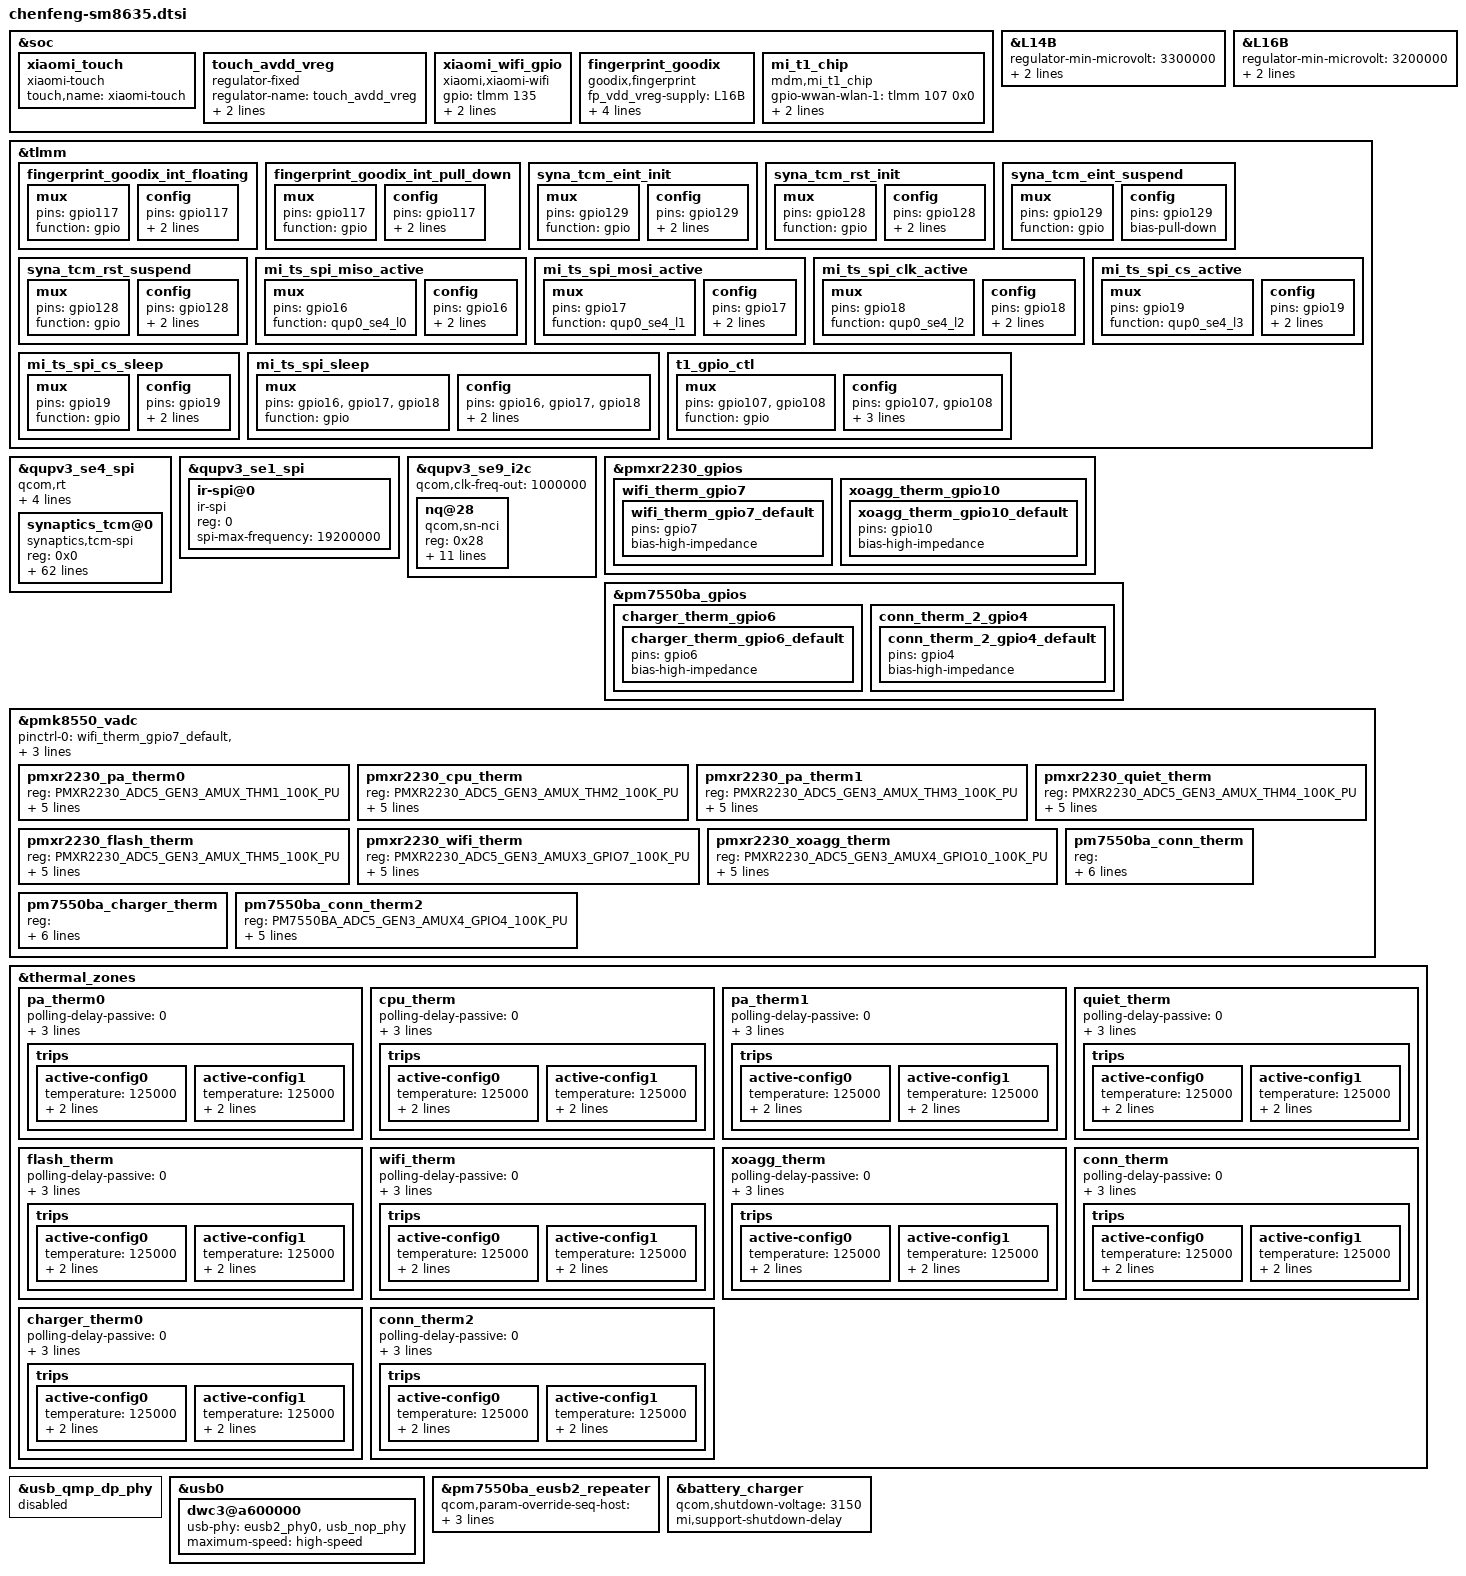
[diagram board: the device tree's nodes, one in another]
/*
  this file is for attribution only of chenfeng
  And public attribution of xiaomi platforms(like N16T and so and)
*/
#define PERIDOT_REGULATOR_OCP_CHENFENG
#include "chenfeng-pinctrl.dtsi"
#include "xiaomi-sm8635-common.dtsi"
#include "cliffs-pm7550ba.dtsi"

&soc {
	xiaomi_touch {
		compatible = "xiaomi-touch";
		status = "ok";
		touch,name = "xiaomi-touch";
	};

	touch_avdd_vreg: touch_avdd_vreg {
		compatible = "regulator-fixed";
		regulator-name = "touch_avdd_vreg";
		/*startup-delay-us = <4000>;*/
		enable-active-high;
		/*regulator-boot-on*/
		gpio = <&tlmm 46 0>;
	};

	xiaomi_wifi_gpio {
		compatible = "xiaomi,xiaomi-wifi";
		gpio = <&tlmm 135 0x00>;
		debounce-time = <30>;
		pinctrl-names = "default";
		pinctrl-0 = <&wifi_ctrl_irq>;
		status = "ok";
	};
};

&L14B {
	regulator-min-microvolt = <3300000>;
	regulator-max-microvolt = <3300000>;
	qcom,init-voltage = <3300000>;
};

&soc {
	fingerprint_goodix {
		compatible = "goodix,fingerprint";
		fp_vdd_vreg-supply = <&L16B>;
		goodix,gpio-reset = <&tlmm 55 0x0>;
		goodix,gpio-irq = <&tlmm 117 0x0>;
		pinctrl-names = "fingerprint_goodix_default", "fingerprint_goodix_rst";
		pinctrl-0 = <&fingerprint_goodix_int_floating>;
		pinctrl-1 = <&fingerprint_goodix_int_pull_down>;
		status = "ok";
	};

	mi_t1_chip {
		compatible = "mdm,mi_t1_chip";
		gpio-wwan-wlan-1 = <&tlmm 107 0x0>;
		gpio-wwan-wlan-2 = <&tlmm 108 0x0>;
		pinctrl-0       = <&t1_gpio_ctl>;
	};
};

&L16B {
	regulator-min-microvolt = <3200000>;
	regulator-max-microvolt = <3200000>;
	qcom,init-voltage = <3200000>;
};

&tlmm {
	fingerprint_goodix_int_floating: fingerprint_goodix_int_floating {
		mux {
			pins = "gpio117";
			function = "gpio";
		};
		config {
			pins = "gpio117";
			input-enable;
			bias-disable;
		};
	};
	fingerprint_goodix_int_pull_down: fingerprint_goodix_int_pull_down {
		mux {
			pins = "gpio117";
			function = "gpio";
		};
		config {
			pins = "gpio117";
			input-enable;
			bias-pull-down;
		};
	};
};

&tlmm {
	syna_tcm_eint_init: syna_tcm_eint_init {
		mux {
			/* GPIO 162 Interrupt */
			pins = "gpio129";
			function = "gpio";
		};

		config {
			pins = "gpio129";
			bias-disable;
			input-enable;
		};
	};

	syna_tcm_rst_init: syna_tcm_rst_init {
		mux {
			/* GPIO 161 Interrupt */
			pins = "gpio128";
			function = "gpio";
		};

		config {
			pins = "gpio128";
			bias-disable;
			output-low;
		};
	};

	syna_tcm_eint_suspend: syna_tcm_eint_suspend {
		mux {
			/* GPIO 162 Interrupt */
			pins = "gpio129";
			function = "gpio";
		};

		config {
			pins = "gpio129";
			bias-pull-down;
		};
	};

	syna_tcm_rst_suspend: syna_tcm_rst_suspend {
		mux {
			/* GPIO 161 Interrupt */
			pins = "gpio128";
			function = "gpio";
		};

		config {
			pins = "gpio128";
			bias-pull-down;
			output-low;
		};
	};
		mi_ts_spi_miso_active: mi_ts_spi_miso_active {
		mux {
			pins = "gpio16";
			function = "qup0_se4_l0";
		};
		config {
			pins = "gpio16";
			drive-strength = <6>;
			bias-pull-down;
		};
	};

	mi_ts_spi_mosi_active: mi_ts_spi_mosi_active {
		mux {
			pins = "gpio17";
			function = "qup0_se4_l1";
		};
		config {
			pins = "gpio17";
			drive-strength = <6>;
			bias-pull-down;
		};
	};

	mi_ts_spi_clk_active: mi_ts_spi_clk_active {
		mux {
			pins = "gpio18";
			function = "qup0_se4_l2";
		};
		config {
			pins = "gpio18";
			drive-strength = <6>;
			bias-pull-down;
		};
	};

	mi_ts_spi_cs_active: mi_ts_spi_cs_active {
		mux {
			pins = "gpio19";
			function = "qup0_se4_l3";
		};
		config {
			pins = "gpio19";
			drive-strength = <6>;
			bias-pull-down;
		};
	};


	mi_ts_spi_cs_sleep: mi_ts_spi_cs_sleep {
		mux {
			pins = "gpio19";
			function = "gpio";
		};
		config {
			pins = "gpio19";
			drive-strength = <6>;
			output-high;
		};
	};


	mi_ts_spi_sleep: mi_ts_spi_sleep {
		mux {
			pins = "gpio16", "gpio17",
				"gpio18";
			function = "gpio";
		};
		config {
			pins = "gpio16", "gpio17",
				"gpio18";
			drive-strength = <2>;
			bias-pull-down;
		};
	};

	t1_gpio_ctl: t1_gpio_ctl {
		mux {
			pins = "gpio107", "gpio108";
			function = "gpio";
		};
		config {
			pins = "gpio107", "gpio108";
			drive-strength = <2>;
			bias-disable;
			output-enable;
		};
	};
};

&qupv3_se4_spi {
	status = "ok";
	qcom,rt;
	pinctrl-0 = <&mi_ts_spi_mosi_active>, <&mi_ts_spi_miso_active>,
		    <&mi_ts_spi_clk_active>, <&mi_ts_spi_cs_active>;
	pinctrl-1 = <&mi_ts_spi_sleep>, <&mi_ts_spi_cs_sleep>;
	synaptics_tcm@0 {
		compatible = "synaptics,tcm-spi";
		reg = <0x0>;
		spi-max-frequency = <10000000>;
		interrupt-parent = <&tlmm>;
		interrupts = <129 0x2008>;
		synaptics,avdd-name = "avdd";
		avdd-supply = <&L14B>;
		synaptics,iovdd-name = "iovdd";
		iovdd-supply = <&touch_avdd_vreg>;
		/*synaptics,bus-reg-name = "vdd";*/
		/*synaptics,pwr-reg-name = "avdd";*/
		synaptics,irq-gpio = <&tlmm 129 0x2008>;
		synaptics,reset-gpio = <&tlmm 128 0x00>;
		synaptics,irq-on-state = <0>;
		synaptics,spi-mode = <0>;
		synaptics,byte-delay-us = <0>;
		synaptics,block-delay-us = <0>;
		synaptics,power-delay-ms = <50>;
		synaptics,reset-active-ms = <10>;
		synaptics,reset-delay-ms = <200>;
		pinctrl-names = "pmx_ts_active","pmx_ts_suspend";
		pinctrl-0 = <&syna_tcm_eint_init &syna_tcm_rst_init>;
		pinctrl-1 = <&syna_tcm_eint_suspend &syna_tcm_rst_suspend>;
		synaptics,default-test-limit-name = "chenfeng_limit_S3905S.csv";
		mi_tp,game-mode-array =
				<1 0 0 0 0>;  /* MAX MIN DEF SET GET	*/
		mi_tp,active-mode-array =
				<1 0 0 0 0>;  /* MAX MIN DEF SET GET	*/
		mi_tp,tolerance-array =
				<4 0 2 2 2>;  /* MAX MIN DEF SET GET	*/
		mi_tp,up-threshold-array =
				<4 0 3 3 3>;  /* MAX MIN DEF SET GET	*/
		mi_tp,aim-sensitivity-array =
				<4 0 2 2 2>;  /* MAX MIN DEF SET GET	*/
		mi_tp,tap-stability-array =
				<4 0 2 2 2>;  /* MAX MIN DEF SET GET	*/
		mi_tp,edge-filter-array =
				<3 0 2 2 2>;  /* MAX MIN DEF SET GET	*/
		mi_tp,panel-orien-array =
				<3 0 0 0 0>;  /* MAX MIN DEF SET GET	*/
		mi_tp,report-rate-array =
				<3 0 0 0 0>;  /* MAX MIN DEF SET GET	*/
		mi_tp,expert-mode-array =
				<3 1 1 1 1>;  /* MAX MIN DEF SET GET	*/
		mi_tp,cornerfilter-area-step-array = <0 100 170 250>; /* step 0 to step 3 */
		mi_tp,cornerzone-filter-hor1-array =
                /* B0:Type, B1:pos, B2:x0, B3:y0, B4:x1, B5:y1, B6:reserved, B7: reserved */
                        <0 0 0 0 170 170 0 0>,
                        <0 1 0 0 0 0 0 0>,
                        <0 2 0 2579 170 2749 0 0>,
                        <0 3 0 0 0 0 0 0>;
		mi_tp,cornerzone-filter-hor2-array =
                /* B0:Type, B1:pos, B2:x0, B3:y0, B4:x1, B5:y1, B6:reserved, B7: reserved */
                        <0 0 0 0 0 0 0 0>,
                        <0 1 1065 0 1235 170 0 0>,
                        <0 2 0 0 0 0 0 0>,
                        <0 3 1065 2579 1235 2749 0 0>;
		mi_tp,cornerzone-filter-ver-array =
                /* B0:Type, B1:pos, B2:x0, B3:y0, B4:x1, B5:y1, B6:reserved, B7: reserved */
                        <0 0 0 0 0 0 0 0>,
                        <0 1 0 0 0 0 0 0>,
                        <0 2 0 2449 150 2749 0 0>,
                        <0 3 1085 2449 1235 2749 0 0>;
		mi_tp,deadzone-filter-hor-array =
                /* B0:Type, B1:pos, B2:x0, B3:y0, B4:x1, B5:y1, B6:reserved, B7: reserved */
                        <2 0 0 0 1235 2 0 0>,
                        <2 1 0 2747 1235 2749 0 0>,
                        <2 2 0 0 2 2749 0 0>,
                        <2 3 1233 0 1235 2479 0 0>;
		mi_tp,deadzone-filter-ver-array =
                /* B0:Type, B1:pos, B2:x0, B3:y0, B4:x1, B5:y1, B6:reserved, B7: reserved */
                        <2 0 0 0 1235 2 0 0>,
                        <2 1 0 2747 1235 2749 0 0>,
                        <2 2 0 0 2 2749 0 0>,
                        <2 3 1233 0 1235 2749 0 0>;
		mi_tp,edgezone-filter-hor-array =
                /* B0:Type, B1:pos, B2:x0, B3:y0, B4:x1, B5:y1, B6:reserved, B7: reserved */
                        <1 0 0 0 1235 40 0 0>,
                        <1 1 0 2709 1235 2749 0 0>,
                        <1 2 0 0 40 2749 0 0>,
                        <1 3 1195 0 1235 2749 0 0>;
		mi_tp,edgezone-filter-ver-array =
                /* B0:Type, B1:pos, B2:x0, B3:y0, B4:x1, B5:y1, B6:reserved, B7: reserved */
                        <1 0 0 0 1235 10 0 0>,
                        <1 1 0 2739 1235 2749 0 0>,
                        <1 2 0 0 40 2749 0 0>,
                        <1 3 1195 0 1235 2749 0 0>;
	};
};

&qupv3_se1_spi {
	status = "ok";
	ir-spi@0 {
		compatible = "ir-spi";
		reg = <0>;
		spi-max-frequency = <19200000>;
		status = "ok";
	};
};

&qupv3_se9_i2c {
	status = "ok";
	qcom,clk-freq-out = <1000000>;
	#address-cells = <1>;
	#size-cells = <0>;
	nq@28 {
		compatible = "qcom,sn-nci";
		reg = <0x28>;
		qcom,sn-irq = <&tlmm 61 0x00>;
		qcom,sn-ven = <&tlmm 114 0x00>;
		qcom,sn-clkreq = <&tlmm 115 0x00>;
		qcom,sn-szone = "enable";
		qcom,sn-vdd-1p8-supply = <&L5B>;
		qcom,sn-vdd-1p8-voltage = <1200000 1200000>;
		qcom,sn-vdd-1p8-current = <157000>;
		interrupt-parent = <&tlmm>;
		interrupts = <61 0>;
		interrupt-names = "nfc_irq";
		pinctrl-names = "nfc_active", "nfc_suspend";
		pinctrl-0 = <&nfc_int_active &nfc_enable_active>;
		pinctrl-1 = <&nfc_int_suspend &nfc_enable_suspend>;
    };
};

&pmxr2230_gpios {
    wifi_therm_gpio7 {
        wifi_therm_gpio7_default: wifi_therm_gpio7_default {
            pins = "gpio7";
            bias-high-impedance;
        };
    };
    xoagg_therm_gpio10 {
        xoagg_therm_gpio10_default: xoagg_therm_gpio10_default {
            pins = "gpio10";
            bias-high-impedance;
        };
    };
};

&pm7550ba_gpios {
    charger_therm_gpio6 {
        charger_therm_gpio6_default: charger_therm_gpio6_default {
            pins = "gpio6";
            bias-high-impedance;
        };
    };
    conn_therm_2_gpio4 {
        conn_therm_2_gpio4_default: conn_therm_2_gpio4_default {
            pins = "gpio4";
            bias-high-impedance;
        };
    };
};
&pmk8550_vadc {
    pinctrl-names = "default";
    pinctrl-0 = <&wifi_therm_gpio7_default &xoagg_therm_gpio10_default &charger_therm_gpio6_default &conn_therm_2_gpio4_default>;

    pmxr2230_pa_therm0 {
        reg = <PMXR2230_ADC5_GEN3_AMUX_THM1_100K_PU>;
        label = "pmxr2230_pa_therm0";
        qcom,ratiometric;
        qcom,hw-settle-time = <200>;
        qcom,pre-scaling = <1 1>;
        qcom,adc-tm-type = <1>;
    };

    pmxr2230_cpu_therm {
        reg = <PMXR2230_ADC5_GEN3_AMUX_THM2_100K_PU>;
        label = "pmxr2230_cpu_therm";
        qcom,ratiometric;
        qcom,hw-settle-time = <200>;
        qcom,pre-scaling = <1 1>;
        qcom,adc-tm-type = <1>;
    };

    pmxr2230_pa_therm1 {
        reg = <PMXR2230_ADC5_GEN3_AMUX_THM3_100K_PU>;
        label = "pmxr2230_pa_therm1";
        qcom,ratiometric;
        qcom,hw-settle-time = <200>;
        qcom,pre-scaling = <1 1>;
        qcom,adc-tm-type = <1>;
    };

    pmxr2230_quiet_therm {
        reg = <PMXR2230_ADC5_GEN3_AMUX_THM4_100K_PU>;
        label = "pmxr2230_quiet_therm";
        qcom,ratiometric;
        qcom,hw-settle-time = <200>;
        qcom,pre-scaling = <1 1>;
        qcom,adc-tm-type = <1>;
    };

    pmxr2230_flash_therm {
        reg = <PMXR2230_ADC5_GEN3_AMUX_THM5_100K_PU>;
        label = "pmxr2230_flash_therm";
        qcom,ratiometric;
        qcom,hw-settle-time = <200>;
        qcom,pre-scaling = <1 1>;
        qcom,adc-tm-type = <1>;
    };

    pmxr2230_wifi_therm {
        reg = <PMXR2230_ADC5_GEN3_AMUX3_GPIO7_100K_PU>;
        label = "pmxr2230_wifi_therm";
        qcom,ratiometric;
        qcom,hw-settle-time = <200>;
        qcom,pre-scaling = <1 1>;
        qcom,adc-tm-type = <1>;
    };

    pmxr2230_xoagg_therm {
        reg = <PMXR2230_ADC5_GEN3_AMUX4_GPIO10_100K_PU>;
        label = "pmxr2230_xoagg_therm";
        qcom,ratiometric;
        qcom,hw-settle-time = <200>;
        qcom,pre-scaling = <1 1>;
        qcom,adc-tm-type = <1>;
    };

    pm7550ba_conn_therm {
            reg = <PM7550BA_ADC5_GEN3_AMUX_THM4_USB_THERM_100K_PU>;
            label = "pm7550ba_conn_therm";
            qcom,ratiometric;
            qcom,hw-settle-time = <200>;
            qcom,pre-scaling = <1 1>;
            qcom,adc-tm-type = <1>;
    };

    pm7550ba_charger_therm {
        reg = <PM7550BA_ADC5_GEN3_AMUX_THM6_GPIO6_100K_PU>;
        label = "pm7550ba_charger_therm";
        qcom,ratiometric;
        qcom,hw-settle-time = <200>;
        qcom,pre-scaling = <1 1>;
        qcom,adc-tm-type = <1>;
    };

    pm7550ba_conn_therm2 {
        reg = <PM7550BA_ADC5_GEN3_AMUX4_GPIO4_100K_PU>;
        label = "pm7550ba_conn_therm2";
        qcom,ratiometric;
        qcom,hw-settle-time = <200>;
        qcom,pre-scaling = <1 1>;
        qcom,adc-tm-type = <1>;
    };
};
&thermal_zones {
    pa_therm0 {
        polling-delay-passive = <0>;
        polling-delay = <0>;
        thermal-sensors = <&pmk8550_vadc PMXR2230_ADC5_GEN3_AMUX_THM1_100K_PU>;
        trips {
            active-config0 {
                temperature = <125000>;
                hysteresis = <1000>;
                type = "passive";
            };
            active-config1 {
                temperature = <125000>;
                hysteresis = <1000>;
                type = "passive";
            };
        };
    };

    cpu_therm {
        polling-delay-passive = <0>;
        polling-delay = <0>;
        thermal-sensors = <&pmk8550_vadc PMXR2230_ADC5_GEN3_AMUX_THM2_100K_PU>;
        trips {
            active-config0 {
                temperature = <125000>;
                hysteresis = <1000>;
                type = "passive";
            };
            active-config1 {
                temperature = <125000>;
                hysteresis = <1000>;
                type = "passive";
            };
        };
    };

    pa_therm1 {
        polling-delay-passive = <0>;
        polling-delay = <0>;
        thermal-sensors = <&pmk8550_vadc PMXR2230_ADC5_GEN3_AMUX_THM3_100K_PU>;
        trips {
            active-config0 {
                temperature = <125000>;
                hysteresis = <1000>;
                type = "passive";
            };
            active-config1 {
                temperature = <125000>;
                hysteresis = <1000>;
                type = "passive";
            };
        };
    };

    quiet_therm {
        polling-delay-passive = <0>;
        polling-delay = <0>;
        thermal-sensors = <&pmk8550_vadc PMXR2230_ADC5_GEN3_AMUX_THM4_100K_PU>;
        trips {
            active-config0 {
                temperature = <125000>;
                hysteresis = <1000>;
                type = "passive";
            };
            active-config1 {
                temperature = <125000>;
                hysteresis = <1000>;
                type = "passive";
            };
        };
    };

    flash_therm {
        polling-delay-passive = <0>;
        polling-delay = <0>;
        thermal-sensors = <&pmk8550_vadc PMXR2230_ADC5_GEN3_AMUX_THM5_100K_PU>;
        trips {
            active-config0 {
                temperature = <125000>;
                hysteresis = <1000>;
                type = "passive";
            };
            active-config1 {
                temperature = <125000>;
                hysteresis = <1000>;
                type = "passive";
            };
        };
    };

    wifi_therm {
        polling-delay-passive = <0>;
        polling-delay = <0>;
        thermal-sensors = <&pmk8550_vadc PMXR2230_ADC5_GEN3_AMUX3_GPIO7_100K_PU>;
        trips {
            active-config0 {
                temperature = <125000>;
                hysteresis = <1000>;
                type = "passive";
            };
            active-config1 {
                temperature = <125000>;
                hysteresis = <1000>;
                type = "passive";
            };
        };
    };

    xoagg_therm {
        polling-delay-passive = <0>;
        polling-delay = <0>;
        thermal-sensors = <&pmk8550_vadc PMXR2230_ADC5_GEN3_AMUX4_GPIO10_100K_PU>;
        trips {
            active-config0 {
                temperature = <125000>;
                hysteresis = <1000>;
                type = "passive";
            };
            active-config1 {
                temperature = <125000>;
                hysteresis = <1000>;
                type = "passive";
			};
		};
    };

    conn_therm {
        polling-delay-passive = <0>;
        polling-delay = <0>;
        thermal-sensors = <&pmk8550_vadc PM7550BA_ADC5_GEN3_AMUX_THM4_USB_THERM_100K_PU>;
        trips {
            active-config0 {
                temperature = <125000>;
                hysteresis = <1000>;
                type = "passive";
            };
            active-config1 {
                temperature = <125000>;
                hysteresis = <1000>;
                type = "passive";
            };
        };
    };

    charger_therm0 {
        polling-delay-passive = <0>;
        polling-delay = <0>;
        thermal-sensors = <&pmk8550_vadc PM7550BA_ADC5_GEN3_AMUX_THM6_GPIO6_100K_PU>;
        trips {
            active-config0 {
                temperature = <125000>;
                hysteresis = <1000>;
                type = "passive";
            };
            active-config1 {
                temperature = <125000>;
                hysteresis = <1000>;
                type = "passive";
            };
        };
    };

    conn_therm2 {
        polling-delay-passive = <0>;
        polling-delay = <0>;
        thermal-sensors = <&pmk8550_vadc PM7550BA_ADC5_GEN3_AMUX4_GPIO4_100K_PU>;
        trips {
            active-config0 {
                temperature = <125000>;
                hysteresis = <1000>;
                type = "passive";
            };
            active-config1 {
                temperature = <125000>;
                hysteresis = <1000>;
                type = "passive";
            };
        };
    };
};

&usb_qmp_dp_phy {
	status = "disabled";
};

&usb0 {
	dwc3@a600000 {
		usb-phy = <&eusb2_phy0>, <&usb_nop_phy>;
		maximum-speed = "high-speed";
	};
};

&pm7550ba_eusb2_repeater {
	qcom,param-override-seq-host =
		<0x00 0x50
		0x0c 0x51
		0x02 0x52
		0x07 0x53
		0x02 0x54
		0x03 0x55
		0x03 0x56
		0x07 0x57
		0x02 0x58
		0x03 0x59
		0x03 0x5a
		0x02 0x5b>;
	qcom,param-override-seq =
		<0x00 0x50
		0x0F 0x51
		0x02 0x52
		0x07 0x53
		0x02 0x54
		0x03 0x55
		0x03 0x56
		0x07 0x57
		0x02 0x58
		0x03 0x59
		0x03 0x5a
		0x02 0x5b>;
};
&battery_charger {
	qcom,shutdown-voltage = <3150>;
	mi,support-shutdown-delay;
};
